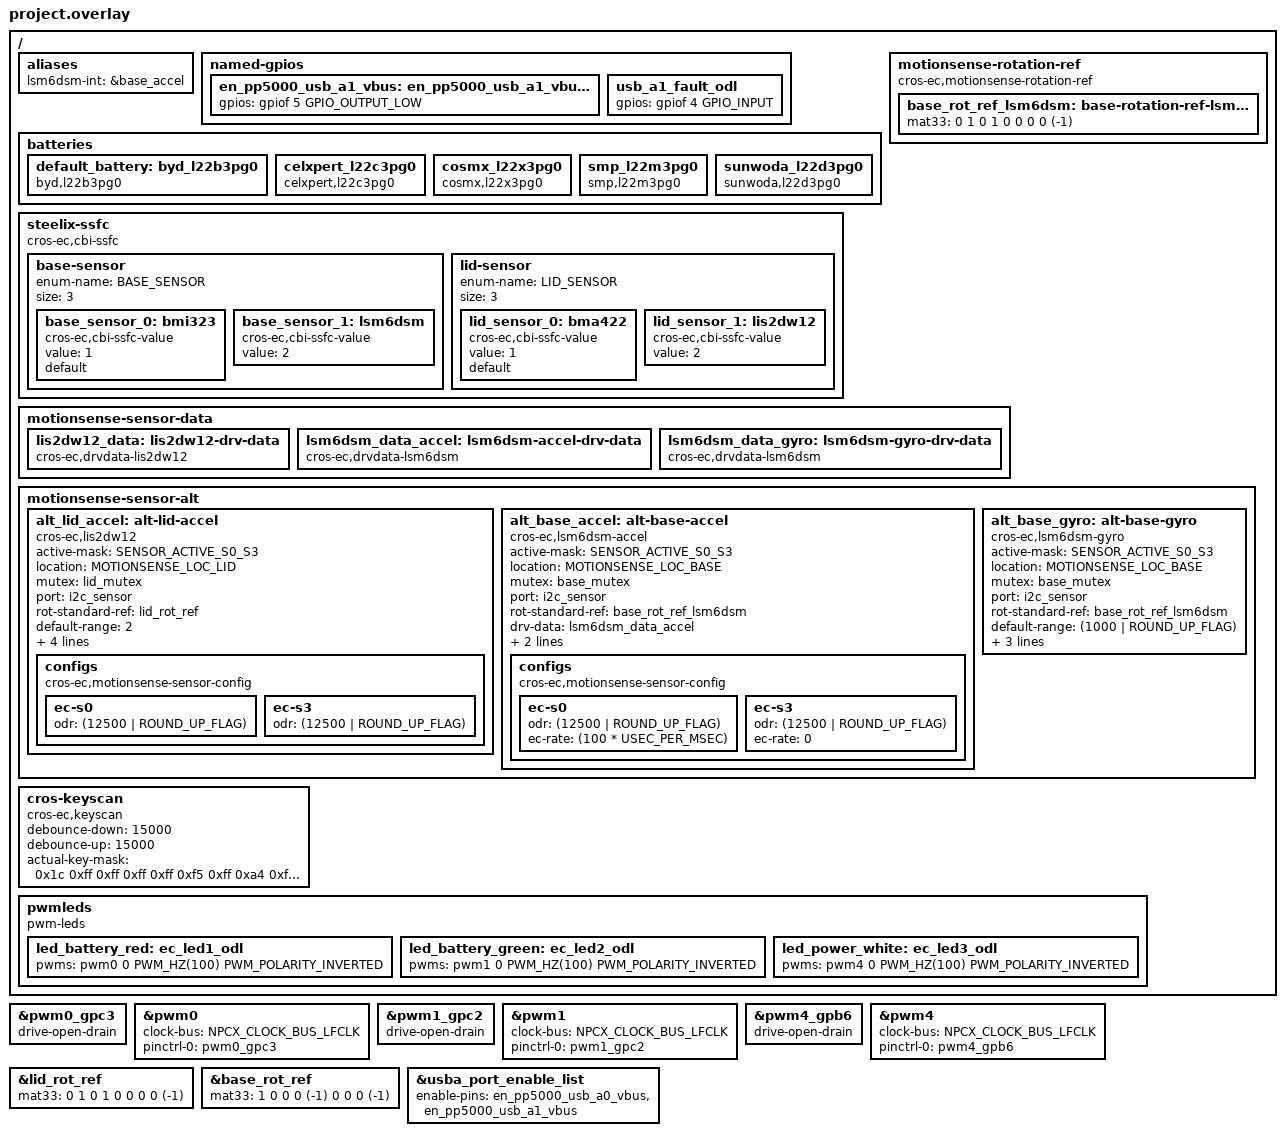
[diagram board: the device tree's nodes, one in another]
/* Copyright 2022 The ChromiumOS Authors
 * Use of this source code is governed by a BSD-style license that can be
 * found in the LICENSE file.
 */

/* Corsola program common DTS includes */

#include "../common.dtsi"
#include "../power_signal.dtsi"
#include "../usba.dtsi"
#include "../npcx_adc.dtsi"
#include "../npcx_gpio.dtsi"
#include "../npcx_host_interface.dtsi"
#include "../npcx_i2c.dtsi"
#include "../npcx_interrupts.dtsi"
#include "../npcx_keyboard.dtsi"
#include "../npcx_motionsense.dtsi"
#include "../npcx_usbc.dtsi"
#include "../npcx_default_gpio_pinctrl.dtsi"

/* Projrect level DTS shared with tests */
#include "./cbi.dtsi"
#include "./interrupts.dtsi"

/* board override */
/ {
	aliases {
		/*
		 * motion sense's <>_INT_EVENT is handled
		 * by alias. Using the alias, each driver creates
		 * its own <>_INT_EVENT.
		 */
		lsm6dsm-int = &base_accel;
	};

	named-gpios {
		en_pp5000_usb_a1_vbus: en_pp5000_usb_a1_vbus_x {
			gpios = <&gpiof 5 GPIO_OUTPUT_LOW>;
		};
		usb_a1_fault_odl {
			gpios = <&gpiof 4 GPIO_INPUT>;
		};
	};

	batteries {
		default_battery: byd_l22b3pg0 {
			compatible = "byd,l22b3pg0", "battery-smart";
		};
		celxpert_l22c3pg0 {
			compatible = "celxpert,l22c3pg0", "battery-smart";
		};
		cosmx_l22x3pg0 {
			compatible = "cosmx,l22x3pg0", "battery-smart";
		};
		smp_l22m3pg0 {
			compatible = "smp,l22m3pg0", "battery-smart";
		};
		sunwoda_l22d3pg0 {
			compatible = "sunwoda,l22d3pg0", "battery-smart";
		};
	};


	/* Steelix-specific ssfc fields. */
	steelix-ssfc {
		compatible = "cros-ec,cbi-ssfc";

		/* SSFC field to identify BASE motion sensor. */
		base-sensor {
			enum-name = "BASE_SENSOR";
			size = <3>;

			base_sensor_0: bmi323 {
				compatible = "cros-ec,cbi-ssfc-value";
				status = "okay";
				value = <1>;
				default;
			};
			base_sensor_1: lsm6dsm {
				compatible = "cros-ec,cbi-ssfc-value";
				status = "okay";
				value = <2>;
			};
		};

		/* SSFC field to identify LID motion sensor. */
		lid-sensor {
			enum-name = "LID_SENSOR";
			size = <3>;

			lid_sensor_0: bma422 {
				compatible = "cros-ec,cbi-ssfc-value";
				status = "okay";
				value = <1>;
				default;
			};
			lid_sensor_1: lis2dw12 {
				compatible = "cros-ec,cbi-ssfc-value";
				status = "okay";
				value = <2>;
			};
		};
	};

	/* Rotation matrix used by drivers. */
	motionsense-rotation-ref {
		compatible = "cros-ec,motionsense-rotation-ref";
		base_rot_ref_lsm6dsm: base-rotation-ref-lsm6dsm {
			mat33 = <0 1 0
				 1 0 0
				 0 0 (-1)>;
		};
	};

	/*
	 * Driver specific data. A driver-specific data can be shared with
	 * different motion sensors while they are using the same driver.
	 *
	 * If a node's compatible starts with "cros-ec,accelgyro-", it is for
	 * a common structure defined in accelgyro.h.
	 * e.g) compatible = "cros-ec,accelgyro-als-drv-data" is for
	 * "struct als_drv_data_t" in accelgyro.h
	 */
	motionsense-sensor-data {
		lis2dw12_data: lis2dw12-drv-data {
			compatible = "cros-ec,drvdata-lis2dw12";
			status = "okay";
		};
		lsm6dsm_data_accel: lsm6dsm-accel-drv-data {
			compatible = "cros-ec,drvdata-lsm6dsm";
			status = "okay";
		};
		lsm6dsm_data_gyro: lsm6dsm-gyro-drv-data {
			compatible = "cros-ec,drvdata-lsm6dsm";
			status = "okay";
		};
	};

	motionsense-sensor-alt {
		alt_lid_accel: alt-lid-accel {
			compatible = "cros-ec,lis2dw12";
			status = "okay";

			active-mask = "SENSOR_ACTIVE_S0_S3";
			location = "MOTIONSENSE_LOC_LID";
			mutex = <&lid_mutex>;
			port = <&i2c_sensor>;
			rot-standard-ref = <&lid_rot_ref>;
			default-range = <2>;
			drv-data = <&lis2dw12_data>;
			i2c-spi-addr-flags = "LIS2DWL_ADDR0_FLAGS";
			alternate-for = <&lid_accel>;
			alternate-ssfc-indicator = <&lid_sensor_1>;
			configs {
				compatible =
					"cros-ec,motionsense-sensor-config";
				ec-s0 {
					odr = <(12500 | ROUND_UP_FLAG)>;
				};
				ec-s3 {
					odr = <(12500 | ROUND_UP_FLAG)>;
				};
			};
		};

		alt_base_accel: alt-base-accel {
			compatible = "cros-ec,lsm6dsm-accel";
			status = "okay";

			active-mask = "SENSOR_ACTIVE_S0_S3";
			location = "MOTIONSENSE_LOC_BASE";
			mutex = <&base_mutex>;
			port = <&i2c_sensor>;
			rot-standard-ref = <&base_rot_ref_lsm6dsm>;
			drv-data = <&lsm6dsm_data_accel>;
			alternate-for = <&base_accel>;
			alternate-ssfc-indicator = <&base_sensor_1>;
			configs {
				compatible =
					"cros-ec,motionsense-sensor-config";
				ec-s0 {
					odr = <(12500 | ROUND_UP_FLAG)>;
					ec-rate = <(100 * USEC_PER_MSEC)>;
				};
				ec-s3 {
					odr = <(12500 | ROUND_UP_FLAG)>;
					ec-rate = <0>;
				};
			};
		};

		alt_base_gyro: alt-base-gyro {
			compatible = "cros-ec,lsm6dsm-gyro";
			status = "okay";

			active-mask = "SENSOR_ACTIVE_S0_S3";
			location = "MOTIONSENSE_LOC_BASE";
			mutex = <&base_mutex>;
			port = <&i2c_sensor>;
			rot-standard-ref = <&base_rot_ref_lsm6dsm>;
			default-range = <(1000 | ROUND_UP_FLAG)>; /* dps */
			drv-data = <&lsm6dsm_data_gyro>;
			alternate-for = <&base_gyro>;
			alternate-ssfc-indicator = <&base_sensor_1>;
		};
	};

	cros-keyscan {
		compatible = "cros-ec,keyscan";

		debounce-down = <15000>;
		debounce-up = <15000>;

		actual-key-mask = <
			0x1c	/* C0 */
			0xff	/* C1 */
			0xff	/* C2 */
			0xff	/* C3 */
			0xff	/* C4 */
			0xf5	/* C5 */
			0xff	/* C6 */
			0xa4	/* C7 */
			0xff	/* C8 */
			0xfe	/* C9 */
			0x55	/* C10 */
			0xfa	/* C11 */
			0xca	/* C12 */
			>;
	};

	pwmleds {
		compatible = "pwm-leds";
		led_battery_red: ec_led1_odl {
			pwms = <&pwm0 0 PWM_HZ(100) PWM_POLARITY_INVERTED>;
		};
		led_battery_green: ec_led2_odl {
			pwms = <&pwm1 0 PWM_HZ(100) PWM_POLARITY_INVERTED>;
		};
		led_power_white: ec_led3_odl {
			pwms = <&pwm4 0 PWM_HZ(100) PWM_POLARITY_INVERTED>;
		};
	};
};

/* Red LED */
&pwm0_gpc3 {
	drive-open-drain;
};

&pwm0 {
	status = "okay";
	clock-bus = "NPCX_CLOCK_BUS_LFCLK";
	pinctrl-0 = <&pwm0_gpc3>;
	pinctrl-names = "default";
};

/* Green LED */
&pwm1_gpc2 {
	drive-open-drain;
};

&pwm1 {
	status = "okay";
	clock-bus = "NPCX_CLOCK_BUS_LFCLK";
	pinctrl-0 = <&pwm1_gpc2>;
	pinctrl-names = "default";
};

/* White LED */
&pwm4_gpb6 {
	drive-open-drain;
};

&pwm4 {
	status = "okay";
	clock-bus = "NPCX_CLOCK_BUS_LFCLK";
	pinctrl-0 = <&pwm4_gpb6>;
	pinctrl-names = "default";
};

/* inherit the rot_ref from Kingler and overwrite it */
&lid_rot_ref {
	mat33 = <0 1 0
		1 0 0
		0 0 (-1)>;
};

&base_rot_ref {
	mat33 = <1 0 0
		0 (-1) 0
		0 0 (-1)>;
};

/* steelix usba port enable config */
&usba_port_enable_list {
	enable-pins = <&en_pp5000_usb_a0_vbus
		       &en_pp5000_usb_a1_vbus>;
};
